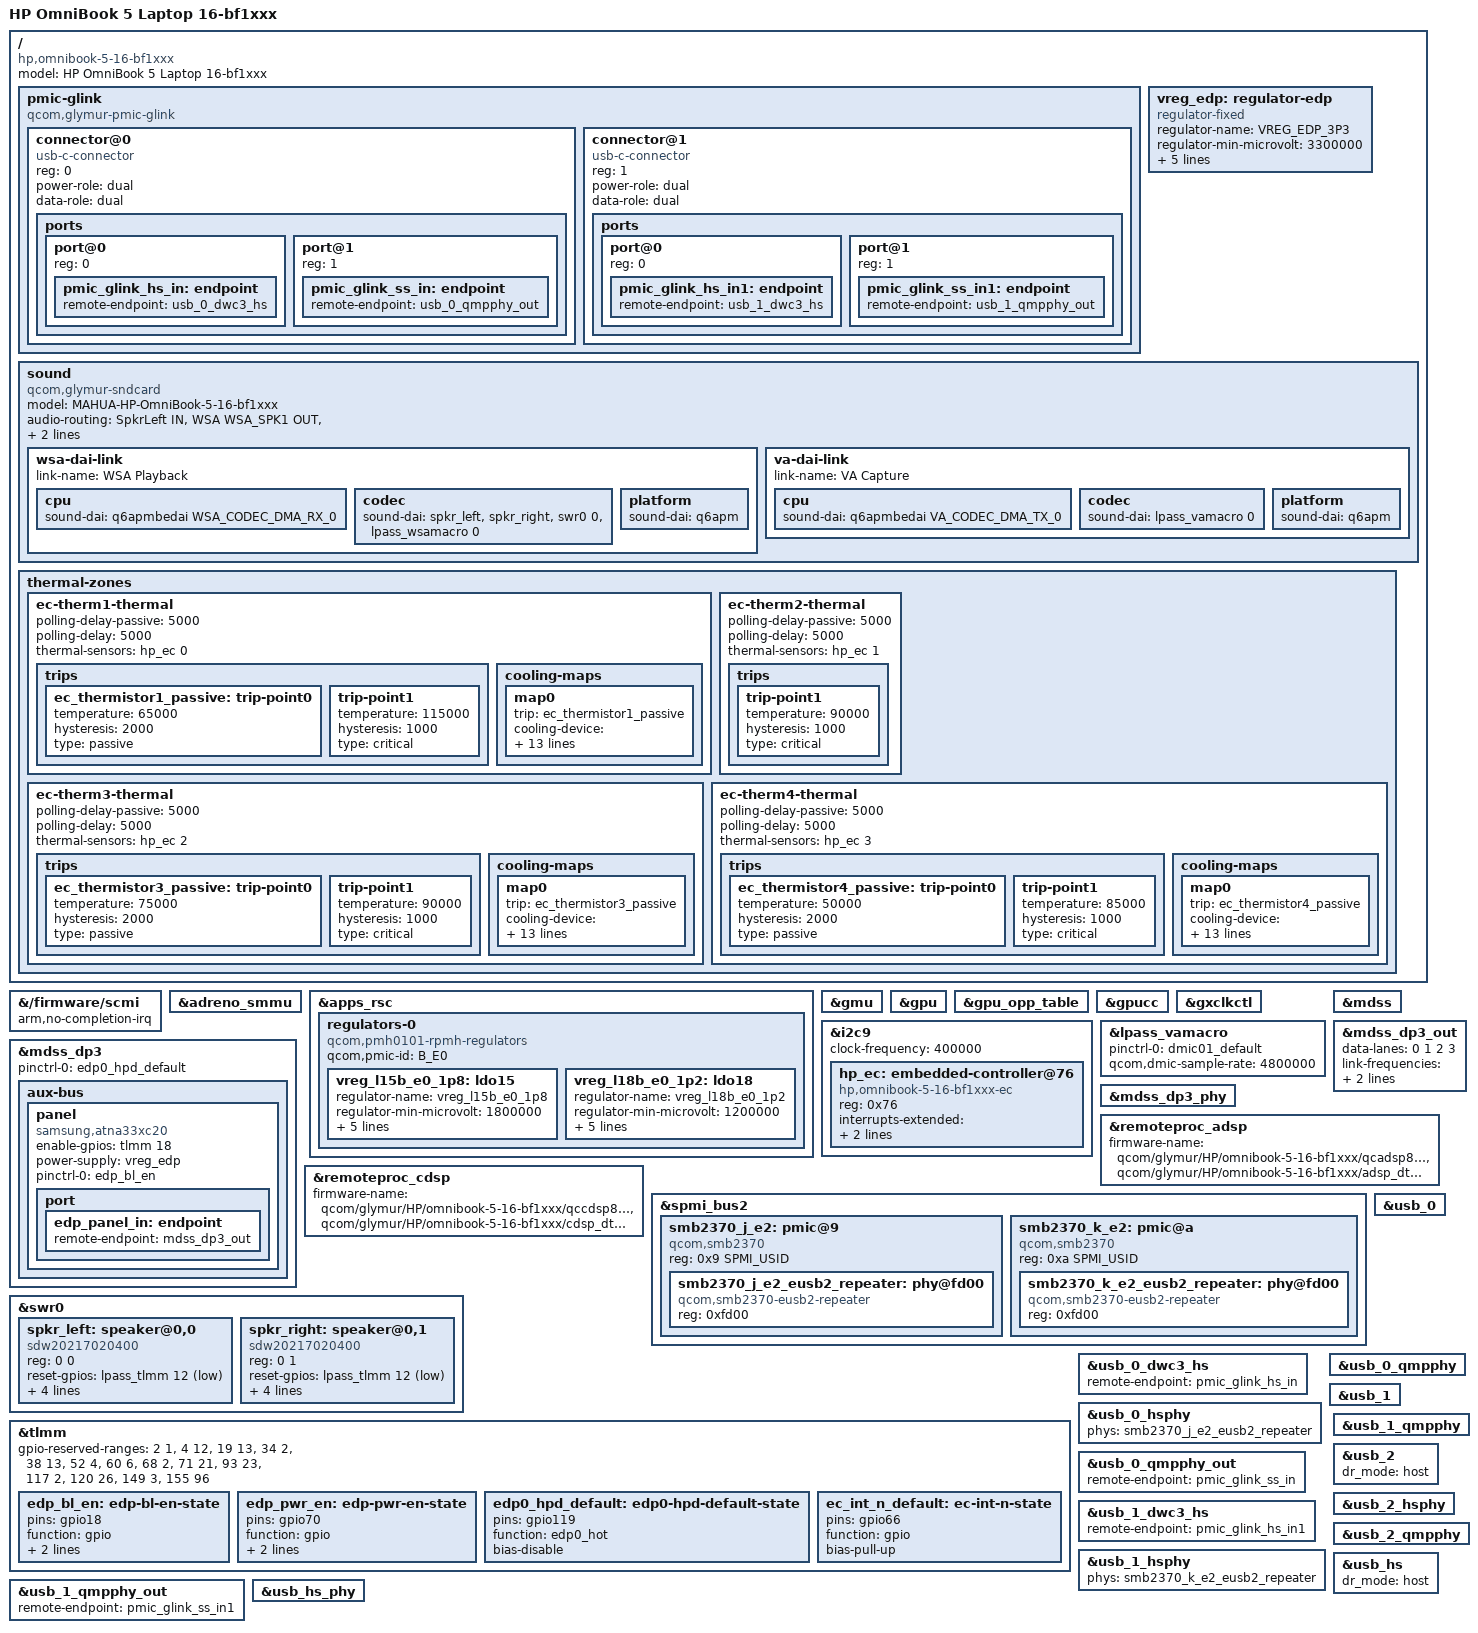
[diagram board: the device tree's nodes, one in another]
// SPDX-License-Identifier: BSD-3-Clause
/*
 * HP OmniBook 5 Laptop 16-bf1xxx
 */
/dts-v1/;

#include <dt-bindings/regulator/qcom,rpmh-regulator.h>
#include <dt-bindings/sound/qcom,q6dsp-lpass-ports.h>
#include "mahua-hp-omnibook-5-bf1xxx.dtsi"

/ {
	model = "HP OmniBook 5 Laptop 16-bf1xxx";
	compatible = "hp,omnibook-5-16-bf1xxx", "qcom,mahua";

	pmic-glink {
		compatible = "qcom,glymur-pmic-glink",
			     "qcom,pmic-glink";
		#address-cells = <1>;
		#size-cells = <0>;

		/* Left side, next to the hinge */
		connector@0 {
			compatible = "usb-c-connector";
			reg = <0>;
			power-role = "dual";
			data-role = "dual";

			ports {
				#address-cells = <1>;
				#size-cells = <0>;

				port@0 {
					reg = <0>;

					pmic_glink_hs_in: endpoint {
						remote-endpoint = <&usb_0_dwc3_hs>;
					};
				};

				port@1 {
					reg = <1>;

					pmic_glink_ss_in: endpoint {
						remote-endpoint = <&usb_0_qmpphy_out>;
					};
				};
			};
		};

		/* Left side, away from the hinge */
		connector@1 {
			compatible = "usb-c-connector";
			reg = <1>;
			power-role = "dual";
			data-role = "dual";

			ports {
				#address-cells = <1>;
				#size-cells = <0>;

				port@0 {
					reg = <0>;

					pmic_glink_hs_in1: endpoint {
						remote-endpoint = <&usb_1_dwc3_hs>;
					};
				};

				port@1 {
					reg = <1>;

					pmic_glink_ss_in1: endpoint {
						remote-endpoint = <&usb_1_qmpphy_out>;
					};
				};
			};
		};
	};

	vreg_edp: regulator-edp {
		compatible = "regulator-fixed";

		regulator-name = "VREG_EDP_3P3";
		regulator-min-microvolt = <3300000>;
		regulator-max-microvolt = <3300000>;

		gpio = <&tlmm 70 GPIO_ACTIVE_HIGH>;
		enable-active-high;

		pinctrl-0 = <&edp_pwr_en>;
		pinctrl-names = "default";

		regulator-boot-on;
	};

	sound: sound {
		compatible = "qcom,glymur-sndcard";
		model = "MAHUA-HP-OmniBook-5-16-bf1xxx";
		audio-routing = "SpkrLeft IN", "WSA WSA_SPK1 OUT",
				"SpkrRight IN", "WSA WSA_SPK2 OUT",
				"VA DMIC0", "vdd-micb",
				"VA DMIC1", "vdd-micb";

		wsa-dai-link {
			link-name = "WSA Playback";

			cpu {
				sound-dai = <&q6apmbedai WSA_CODEC_DMA_RX_0>;
			};

			codec {
				sound-dai = <&spkr_left>, <&spkr_right>,
					    <&swr0 0>, <&lpass_wsamacro 0>;
			};

			platform {
				sound-dai = <&q6apm>;
			};
		};

		va-dai-link {
			link-name = "VA Capture";

			cpu {
				sound-dai = <&q6apmbedai VA_CODEC_DMA_TX_0>;
			};

			codec {
				sound-dai = <&lpass_vamacro 0>;
			};

			platform {
				sound-dai = <&q6apm>;
			};
		};
	};

	/* Skin temperature, on the EC's four thermistors */
	thermal-zones {
		ec-therm1-thermal {
			polling-delay-passive = <5000>;
			polling-delay = <5000>;
			thermal-sensors = <&hp_ec 0>;

			trips {
				ec_thermistor1_passive: trip-point0 {
					temperature = <65000>;
					hysteresis = <2000>;
					type = "passive";
				};

				trip-point1 {
					temperature = <115000>;
					hysteresis = <1000>;
					type = "critical";
				};
			};

			cooling-maps {
				map0 {
					trip = <&ec_thermistor1_passive>;
					cooling-device = <&cpu0 THERMAL_NO_LIMIT THERMAL_NO_LIMIT>,
							 <&cpu1 THERMAL_NO_LIMIT THERMAL_NO_LIMIT>,
							 <&cpu2 THERMAL_NO_LIMIT THERMAL_NO_LIMIT>,
							 <&cpu3 THERMAL_NO_LIMIT THERMAL_NO_LIMIT>,
							 <&cpu4 THERMAL_NO_LIMIT THERMAL_NO_LIMIT>,
							 <&cpu5 THERMAL_NO_LIMIT THERMAL_NO_LIMIT>,
							 <&cpu6 THERMAL_NO_LIMIT THERMAL_NO_LIMIT>,
							 <&cpu7 THERMAL_NO_LIMIT THERMAL_NO_LIMIT>,
							 <&cpu8 THERMAL_NO_LIMIT THERMAL_NO_LIMIT>,
							 <&cpu9 THERMAL_NO_LIMIT THERMAL_NO_LIMIT>,
							 <&cpu10 THERMAL_NO_LIMIT THERMAL_NO_LIMIT>,
							 <&cpu11 THERMAL_NO_LIMIT THERMAL_NO_LIMIT>,
							 <&gpu THERMAL_NO_LIMIT THERMAL_NO_LIMIT>;
				};
			};
		};

		ec-therm2-thermal {
			polling-delay-passive = <5000>;
			polling-delay = <5000>;
			thermal-sensors = <&hp_ec 1>;

			trips {
				trip-point1 {
					temperature = <90000>;
					hysteresis = <1000>;
					type = "critical";
				};
			};
		};

		ec-therm3-thermal {
			polling-delay-passive = <5000>;
			polling-delay = <5000>;
			thermal-sensors = <&hp_ec 2>;

			trips {
				ec_thermistor3_passive: trip-point0 {
					temperature = <75000>;
					hysteresis = <2000>;
					type = "passive";
				};

				trip-point1 {
					temperature = <90000>;
					hysteresis = <1000>;
					type = "critical";
				};
			};

			cooling-maps {
				map0 {
					trip = <&ec_thermistor3_passive>;
					cooling-device = <&cpu0 THERMAL_NO_LIMIT THERMAL_NO_LIMIT>,
							 <&cpu1 THERMAL_NO_LIMIT THERMAL_NO_LIMIT>,
							 <&cpu2 THERMAL_NO_LIMIT THERMAL_NO_LIMIT>,
							 <&cpu3 THERMAL_NO_LIMIT THERMAL_NO_LIMIT>,
							 <&cpu4 THERMAL_NO_LIMIT THERMAL_NO_LIMIT>,
							 <&cpu5 THERMAL_NO_LIMIT THERMAL_NO_LIMIT>,
							 <&cpu6 THERMAL_NO_LIMIT THERMAL_NO_LIMIT>,
							 <&cpu7 THERMAL_NO_LIMIT THERMAL_NO_LIMIT>,
							 <&cpu8 THERMAL_NO_LIMIT THERMAL_NO_LIMIT>,
							 <&cpu9 THERMAL_NO_LIMIT THERMAL_NO_LIMIT>,
							 <&cpu10 THERMAL_NO_LIMIT THERMAL_NO_LIMIT>,
							 <&cpu11 THERMAL_NO_LIMIT THERMAL_NO_LIMIT>,
							 <&gpu THERMAL_NO_LIMIT THERMAL_NO_LIMIT>;
				};
			};
		};

		ec-therm4-thermal {
			polling-delay-passive = <5000>;
			polling-delay = <5000>;
			thermal-sensors = <&hp_ec 3>;

			trips {
				ec_thermistor4_passive: trip-point0 {
					temperature = <50000>;
					hysteresis = <2000>;
					type = "passive";
				};

				trip-point1 {
					temperature = <85000>;
					hysteresis = <1000>;
					type = "critical";
				};
			};

			cooling-maps {
				map0 {
					trip = <&ec_thermistor4_passive>;
					cooling-device = <&cpu0 THERMAL_NO_LIMIT THERMAL_NO_LIMIT>,
							 <&cpu1 THERMAL_NO_LIMIT THERMAL_NO_LIMIT>,
							 <&cpu2 THERMAL_NO_LIMIT THERMAL_NO_LIMIT>,
							 <&cpu3 THERMAL_NO_LIMIT THERMAL_NO_LIMIT>,
							 <&cpu4 THERMAL_NO_LIMIT THERMAL_NO_LIMIT>,
							 <&cpu5 THERMAL_NO_LIMIT THERMAL_NO_LIMIT>,
							 <&cpu6 THERMAL_NO_LIMIT THERMAL_NO_LIMIT>,
							 <&cpu7 THERMAL_NO_LIMIT THERMAL_NO_LIMIT>,
							 <&cpu8 THERMAL_NO_LIMIT THERMAL_NO_LIMIT>,
							 <&cpu9 THERMAL_NO_LIMIT THERMAL_NO_LIMIT>,
							 <&cpu10 THERMAL_NO_LIMIT THERMAL_NO_LIMIT>,
							 <&cpu11 THERMAL_NO_LIMIT THERMAL_NO_LIMIT>,
							 <&gpu THERMAL_NO_LIMIT THERMAL_NO_LIMIT>;
				};
			};
		};
	};
};

&{/firmware/scmi} {
	/* The CPUCP firmware does not raise the completion interrupt */
	arm,no-completion-irq;
};

&adreno_smmu {
	status = "okay";
};

&apps_rsc {
	regulators-0 {
		compatible = "qcom,pmh0101-rpmh-regulators";
		qcom,pmic-id = "B_E0";

		/* Shared with the USB PHYs and repeaters */
		vreg_l15b_e0_1p8: ldo15 {
			regulator-name = "vreg_l15b_e0_1p8";
			regulator-min-microvolt = <1800000>;
			regulator-max-microvolt = <1800000>;
			regulator-initial-mode = <RPMH_REGULATOR_MODE_HPM>;
			regulator-always-on;
			regulator-boot-on;
		};

		/* Shared with the display */
		vreg_l18b_e0_1p2: ldo18 {
			regulator-name = "vreg_l18b_e0_1p2";
			regulator-min-microvolt = <1200000>;
			regulator-max-microvolt = <1200000>;
			regulator-initial-mode = <RPMH_REGULATOR_MODE_HPM>;
			regulator-always-on;
			regulator-boot-on;
		};
	};
};

&gmu {
	status = "okay";
};

&gpu {
	status = "okay";
};

&gpu_opp_table {
	/delete-node/ opp-1550000000;
	/delete-node/ opp-1700000000;
	/delete-node/ opp-1850000000;
};

&gpucc {
	status = "okay";
};

&gxclkctl {
	status = "okay";
};

&i2c9 {
	clock-frequency = <400000>;

	status = "okay";

	hp_ec: embedded-controller@76 {
		compatible = "hp,omnibook-5-16-bf1xxx-ec";
		reg = <0x76>;

		interrupts-extended = <&tlmm 66 IRQ_TYPE_EDGE_FALLING>;

		pinctrl-0 = <&ec_int_n_default>;
		pinctrl-names = "default";

		#thermal-sensor-cells = <1>;
	};
};

&lpass_vamacro {
	pinctrl-0 = <&dmic01_default>;
	pinctrl-names = "default";
	qcom,dmic-sample-rate = <4800000>;
};

&mdss {
	status = "okay";
};

&mdss_dp3 {
	/delete-property/ #sound-dai-cells;

	pinctrl-0 = <&edp0_hpd_default>;
	pinctrl-names = "default";

	status = "okay";

	aux-bus {
		panel {
			compatible = "samsung,atna33xc20";
			enable-gpios = <&tlmm 18 GPIO_ACTIVE_HIGH>;
			power-supply = <&vreg_edp>;

			pinctrl-0 = <&edp_bl_en>;
			pinctrl-names = "default";

			port {
				edp_panel_in: endpoint {
					remote-endpoint = <&mdss_dp3_out>;
				};
			};
		};
	};
};

&mdss_dp3_out {
	data-lanes = <0 1 2 3>;
	link-frequencies = /bits/ 64 <1620000000 2700000000 5400000000 8100000000>;

	remote-endpoint = <&edp_panel_in>;
};

&mdss_dp3_phy {
	status = "okay";
};

&remoteproc_adsp {
	firmware-name = "qcom/glymur/HP/omnibook-5-16-bf1xxx/qcadsp8480.mbn",
			"qcom/glymur/HP/omnibook-5-16-bf1xxx/adsp_dtbs.elf";

	status = "okay";
};

&remoteproc_cdsp {
	firmware-name = "qcom/glymur/HP/omnibook-5-16-bf1xxx/qccdsp8480.mbn",
			"qcom/glymur/HP/omnibook-5-16-bf1xxx/cdsp_dtbs.elf";

	status = "okay";
};

&spmi_bus2 {
	smb2370_j_e2: pmic@9 {
		compatible = "qcom,smb2370", "qcom,spmi-pmic";
		reg = <0x9 SPMI_USID>;
		#address-cells = <1>;
		#size-cells = <0>;

		smb2370_j_e2_eusb2_repeater: phy@fd00 {
			compatible = "qcom,smb2370-eusb2-repeater";
			reg = <0xfd00>;
			#phy-cells = <0>;
		};
	};

	smb2370_k_e2: pmic@a {
		compatible = "qcom,smb2370", "qcom,spmi-pmic";
		reg = <0xa SPMI_USID>;
		#address-cells = <1>;
		#size-cells = <0>;

		smb2370_k_e2_eusb2_repeater: phy@fd00 {
			compatible = "qcom,smb2370-eusb2-repeater";
			reg = <0xfd00>;
			#phy-cells = <0>;
		};
	};
};

&swr0 {
	status = "okay";

	/* WSA8845 */
	spkr_left: speaker@0,0 {
		compatible = "sdw20217020400";
		reg = <0 0>;
		reset-gpios = <&lpass_tlmm 12 GPIO_ACTIVE_LOW>;
		#sound-dai-cells = <0>;
		sound-name-prefix = "SpkrLeft";
		vdd-1p8-supply = <&vreg_l15b_e0_1p8>;
		vdd-io-supply = <&vreg_l18b_e0_1p2>;
		qcom,port-mapping = <1 2 3 7 12 14>;
	};

	/* WSA8845 */
	spkr_right: speaker@0,1 {
		compatible = "sdw20217020400";
		reg = <0 1>;
		reset-gpios = <&lpass_tlmm 12 GPIO_ACTIVE_LOW>;
		#sound-dai-cells = <0>;
		sound-name-prefix = "SpkrRight";
		vdd-1p8-supply = <&vreg_l15b_e0_1p8>;
		vdd-io-supply = <&vreg_l18b_e0_1p2>;
		qcom,port-mapping = <4 5 6 7 13 15>;
	};
};

&tlmm {
	gpio-reserved-ranges = <2 1>, <4 12>, <19 13>, <34 2>, <38 13>,
			       <52 4>, <60 6>, <68 2>, <71 21>, <93 23>,
			       <117 2>, <120 26>, <149 3>, <155 96>;

	edp_bl_en: edp-bl-en-state {
		pins = "gpio18";
		function = "gpio";
		drive-strength = <16>;
		bias-disable;
	};

	edp_pwr_en: edp-pwr-en-state {
		pins = "gpio70";
		function = "gpio";
		drive-strength = <16>;
		bias-disable;
	};

	edp0_hpd_default: edp0-hpd-default-state {
		pins = "gpio119";
		function = "edp0_hot";
		bias-disable;
	};

	ec_int_n_default: ec-int-n-state {
		pins = "gpio66";
		function = "gpio";
		bias-pull-up;
	};
};

&usb_0 {
	status = "okay";
};

&usb_0_dwc3_hs {
	remote-endpoint = <&pmic_glink_hs_in>;
};

&usb_0_hsphy {
	phys = <&smb2370_j_e2_eusb2_repeater>;

	status = "okay";
};

&usb_0_qmpphy {
	status = "okay";
};

&usb_0_qmpphy_out {
	remote-endpoint = <&pmic_glink_ss_in>;
};

&usb_1 {
	status = "okay";
};

&usb_1_dwc3_hs {
	remote-endpoint = <&pmic_glink_hs_in1>;
};

&usb_1_hsphy {
	phys = <&smb2370_k_e2_eusb2_repeater>;

	status = "okay";
};

&usb_1_qmpphy {
	status = "okay";
};

&usb_1_qmpphy_out {
	remote-endpoint = <&pmic_glink_ss_in1>;
};

/* USB-A, right side */
&usb_2 {
	dr_mode = "host";
	/delete-property/ usb-role-switch;

	status = "okay";
};

&usb_2_hsphy {
	status = "okay";
};

&usb_2_qmpphy {
	status = "okay";
};

/* Camera */
&usb_hs {
	dr_mode = "host";
	/delete-property/ usb-role-switch;

	status = "okay";
};

&usb_hs_phy {
	status = "okay";
};
